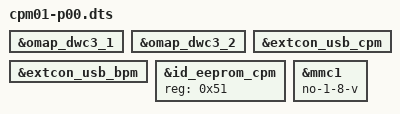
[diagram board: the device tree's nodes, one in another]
/*
 * Copyright 2020-2023 Hitachi Energy.
 *
 * This program is free software; you can redistribute it and/or modify
 * it under the terms of the GNU General Public License version 2 as
 * published by the Free Software Foundation.
 */
 
 #include "cpm01-p01.dts"

&omap_dwc3_1 {
	/delete-property/ extcon;
};

&omap_dwc3_2 {
	/delete-property/ extcon;
};

/* we cannot delete extcon_usb_cpm node because it's used in alias. So we delete the properties instead*/
&extcon_usb_cpm {
/delete-property/ vbus-gpio;
/delete-property/ id-gpio;
/delete-property/ vbus-out-gpio;
};

&extcon_usb_bpm {
/delete-property/ vbus-gpio;
/delete-property/ id-gpio;
/delete-property/ vbus-out-gpio;
};

&id_eeprom_cpm {
	reg = <0x51>;
};

&mmc1 {
	no-1-8-v;
	pinctrl-names = "default", "hs";
	/delete-property/ pinctrl-2;
};

/delete-node/ &sfp_ddmi10;

